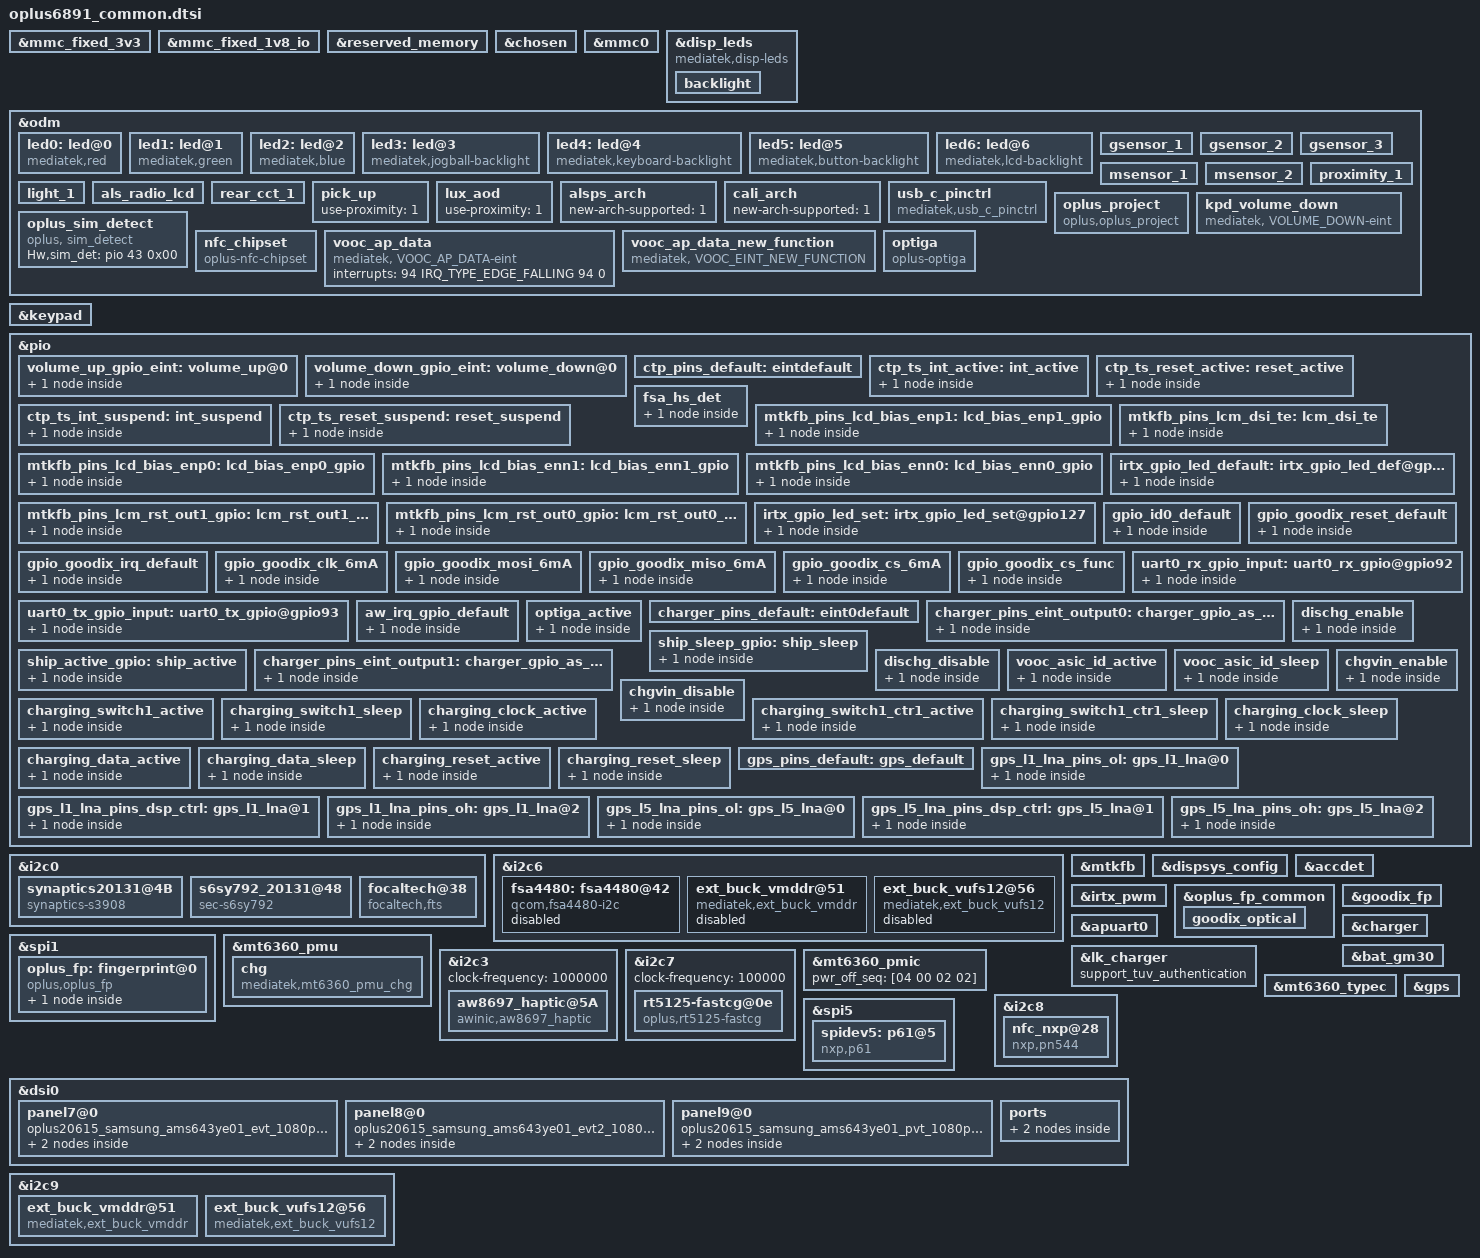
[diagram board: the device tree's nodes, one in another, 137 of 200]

&mmc_fixed_3v3 {
	status = "okay";
	regulator-name = "mmc_power";
	regulator-min-microvolt = <3300000>;
	regulator-max-microvolt = <3300000>;
	enable-active-high;
	regulator-always-on;
};

&mmc_fixed_1v8_io {
	status = "okay";
	regulator-name = "mmc_io";
	regulator-min-microvolt = <1800000>;
	regulator-max-microvolt = <1800000>;
	enable-active-high;
	regulator-always-on;
};

&reserved_memory {
};

/* chosen */
&chosen {

	atag,videolfb-fb_base_l = <0x7e020000>;
	atag,videolfb-fb_base_h = <0x0>;
	atag,videolfb-islcmfound = <1>;
	atag,videolfb-islcm_inited = <0>;
	atag,videolfb-fps= <6000>;
	atag,videolfb-vramSize= <0x1be0000>;
	atag,videolfb-lcmname=
		"nt35595_fhd_dsi_cmd_truly_nt50358_drv";
};

&mmc0 {
	status = "okay";
	/* pinctrl-names = "default", "state_uhs"; */
	/* pinctrl-0 = <&mmc0_pins_default>; */
	/* pinctrl-1 = <&mmc0_pins_uhs>; */
	bus-width = <8>;
	max-frequency = <5000000>;
	cap-mmc-highspeed;
	no-sdio;
	no-sd;
	vmmc-supply = <&mmc_fixed_3v3>;
	vqmmc-supply = <&mmc_fixed_1v8_io>;
	non-removable;
};

&disp_leds {
	compatible = "mediatek,disp-leds";

	backlight {
		label = "lcd-backlight";
		max-brightness = <4095>;
		led-bits = <12>;
		trans-bits = <12>;
		default-state = "on";
	};
};

&odm {
	led0:led@0 {
		compatible = "mediatek,red";
		led_mode = <0>;
		data = <1>;
		pwm_config = <0 0 0 0 0>;
	};
	led1:led@1 {
		compatible = "mediatek,green";
		led_mode = <0>;
		data = <1>;
		pwm_config = <0 0 0 0 0>;
	};
	led2:led@2 {
		compatible = "mediatek,blue";
		led_mode = <0>;
		data = <1>;
		pwm_config = <0 0 0 0 0>;
	};
	led3:led@3 {
		compatible = "mediatek,jogball-backlight";
		led_mode = <0>;
		data = <1>;
		pwm_config = <0 0 0 0 0>;
	};
	led4:led@4 {
		compatible = "mediatek,keyboard-backlight";
		led_mode = <0>;
		data = <1>;
		pwm_config = <0 0 0 0 0>;
	};
	led5:led@5 {
		compatible = "mediatek,button-backlight";
		led_mode = <0>;
		data = <1>;
		pwm_config = <0 0 0 0 0>;
	};
	led6:led@6 {
		compatible = "mediatek,lcd-backlight";
		/*#ifndef OPLUS_FEATURE_BRINGUP*/
		//led_mode = <5>;
		//#else
		led_mode = <4>;
		//#endif
		data = <1>;
		pwm_config = <0 1 0 0 0>;
	};
/* sensor start */
	/*
	enum {
		LIS3DH,
		LSM6DS3,
		BMI160,
		LIS2HH12,
		LSM6DSM,
		BMI2XY,
		LSM6DSO,
		BMA2X2,
		SC7A20,
		ICM4X6XX,
		ICM4N607,
	};
	*/
	gsensor_1: gsensor_1 {
		status = "okay";
		sensor_name = <2>;//BMI160
		device_name = "bmi160";
		i2c_num = <2>;
		i2c_addr = <0>;
		direction = <7>;
		eint_num = <3>;
		step_count_7_en = <1>;
		config_miso = <1>;
		correct_y_bias = <1>;
		gyro_cali_version= <2>;
		acc_cali_range= <250 250 250>; //250mg
	};
	gsensor_2: gsensor_2 {
		status = "okay";
		sensor_name = <6>;//LSM6DSO
		device_name = "lsm6dso";
		i2c_num = <2>;
		i2c_addr = <0>;
		direction = <6>;
		eint_num = <3>;
		gyro_cali_version= <2>;
		acc_cali_range= <200 200 200>; //250mg
	};
	gsensor_3: gsensor_3 {
		status = "okay";
		sensor_name = <10>;//ICM42607
		device_name = "icm4n607";
		i2c_num = <2>;
		i2c_addr = <0>;
		direction = <6>;
		eint_num = <3>;
		gyro_cali_version= <2>;
		acc_cali_range= <300 300 300>; //300mg
	};
	/*
	enum {
		AKM09911,
		MMC3530,
		MMC5603,
		MXG4300,
	};
	*/
	msensor_1: msensor_1 {
		status = "okay";
		sensor_name = <0>;//AKM09911
		i2c_num = <0>;
		i2c_addr = <12>;
		direction = <1>;
		eint_num = <0>;
		soft-mag-parameter = <11168 0 285 1 86 1 218 1 9025 0 78 1 263 1 31 0 10658 0>;
	};
	msensor_2: msensor_2 {
		status = "okay";
		sensor_name = <2>;//MMC5603
		i2c_num = <0>;
		i2c_addr = <48>;
		direction = <1>;
		eint_num = <0>;
		soft-mag-parameter = <9983 0 495 1 111 0 42 0 8099 0 453 1 515 0 155 1 10267 0>;
	};
	/*
	enum {
		TMD2725,
		APSD9922,
		STK3335,
		STK3331,
		STK2232,
		TCS3701,
		STK32600,
	};
	*/
	proximity_1: proximity_1 {
		status = "okay";
		sensor_name = <5>;//TCS3701
		i2c_num = <0>;
		i2c_addr = <57>;
		direction = <4>;
		eint_num = <4>;
		low_step = <300>;
		high_step = <400>;
		low_limit = <400>;
		high_limit = <600>;
		dirty_low_step = <100>;
		dirty_high_step = <150>;
		ps_dirty_limit = <1022>;
		ps_ir_limit = <500>;
		ps_adjust_min = <0>;
		ps_adjust_max = <600>;
		sampling_count = <5>;
		step_max = <400>;
		step_min = <110>;
		step_div = <1500>;
		anti_shake_delta = <80>;
		dynamic_cali_max = <1023>;
		raw2offset_radio = <31200>;
		offset_max = <250>;
		offset_range_min = <255>;
		offset_range_max = <255>;
		force_cali_limit = <2000>;
		cali_jitter_limit = <30>;
		cal_offset_margin = <120>;
	};
	light_1: light_1 {
		status = "okay";
		sensor_name = <5>;//TCS3701
		i2c_num = <0>;
		i2c_addr = <57>;
		direction = <4>;
		eint_num = <4>;
		als_ratio = <110>;
		als_buffer_length =<10>;
		device_name = "tcs3701";
	};
	als_radio_lcd:als_radio_lcd {
		status = "okay";
		samsung_als_radio = <200>;
		boe_als_radio = <150>;
		tianma_als_radio = <150>;
	};
	rear_cct_1: rear_cct_1 {
                status = "okay";
                sensor_name = <1>;//MN29005
                i2c_num = <1>;
                i2c_addr = <0x49>;
                direction = <0>;
                eint_num = <8>;
                available_sensor = <1>; // bit 0: rear als, bit 1: rear cct, bit 2: rear flicker
                device_name = "mn29005";
        };
	pick_up: pick_up {
		status = "okay";
		use-proximity = <1>;
	};
	lux_aod: lux_aod {
		status = "okay";
		use-proximity = <1>;
	};
	alsps_arch: alsps_arch {
		status = "okay";
		new-arch-supported = <1>;
	};
	cali_arch: cali_arch {
		status = "okay";
		new-arch-supported = <1>;
	};
/* sensor end */
	usb_c_pinctrl:usb_c_pinctrl {
		compatible = "mediatek,usb_c_pinctrl";
	};
/*OPLUS_FEATURE_TP_BASIC oplus project start */
	oplus_project:oplus_project {
		compatible = "oplus,oplus_project";
	};
/*endif*/
//#ifdef OPLUS_FEATURE_TP_BASIC
        kpd_volume_down:kpd_volume_down {
                compatible = "mediatek, VOLUME_DOWN-eint";
                interrupt-parent = <&pio>;
                interrupts = <155 IRQ_TYPE_EDGE_FALLING 155 0>;
                debounce = <32000>;
                status = "okay";
        };

//#endif OPLUS_FEATURE_TP_BASIC

//#ifdef OPLUS_FEATURE_TP_BASIC
    oplus_sim_detect {
        compatible = "oplus, sim_detect";
        Hw,sim_det = <&pio 43 0x00>;
    };
//#endif /* OPLUS_FEATURE_TP_BASIC */

    nfc_chipset:nfc_chipset {
        compatible = "oplus-nfc-chipset";
        chipset-20615 = "SN100T";
        chipset-20662 = "SN100T";
    };
//#endif /* OPLUS_FEATURE_NFC_CONSOFT */

};
//#ifdef OPLUS_FEATURE_TP_BASIC
&keypad {
        keypad,volume-up        = <&pio 20 0x00>;
        keypad,volume-down      = <&pio 155 0x00>;
        pinctrl-names = "volume_up_as_int", "volume_down_as_int";
        pinctrl-0 = <&volume_up_gpio_eint>;
        pinctrl-1 = <&volume_down_gpio_eint>;
        status = "okay";
};

&pio {
        volume_up_gpio_eint:volume_up@0{
                pins_cmd_dat {
                        pinmux = <PINMUX_GPIO59__FUNC_GPIO59>;
                        slew-rate = <0>;  /*direction 0:in, 1:out*/
                        input-enable;
                };
        };

        volume_down_gpio_eint:volume_down@0{
                pins_cmd_dat {
                        pinmux = <PINMUX_GPIO155__FUNC_GPIO155>;
                        slew-rate = <0>;  /*direction 0:in, 1:out*/
                        input-enable;
                };
        };
};
//#endif OPLUS_FEATURE_TP_BASIC
//#ifdef OPLUS_FEATURE_TP_BASIC
&i2c0 {

	synaptics20131@4B {
		compatible = "synaptics-s3908";
		reg = <0x4B>;
		chip-name = "S3908";

		/* Interrupt && Irq-gpio */
		interrupt-parent = <&pio>;
		interrupts = <21 0x2008>;

		/* Power Config */
		vdd_2v8-supply  = <&mt_pmic_vtp_ldo_reg>;
		vdd_2v8_volt = <3000000>;
		/* Other HW Resource */

		irq-gpio = <&pio 21 0x2008>;
		reset-gpio = <&pio 20 0x1>;
		pinctrl-names = "default";
		pinctrl-0 = <&ctp_ts_int_active &ctp_ts_reset_suspend>;

		touchpanel,max-num-support = <10>;
                touchpanel,tx-rx-num = <16 36>;
                touchpanel,panel-coords = <5400 12000>;
                touchpanel,display-coords = <1080 2400>;
                touchpanel,touchmajor-limit = <160 270>;
		//touchpanel,elimination-range = <20 200 200>;
                touchpanel,int-mode = <1>; /*0: interrupt and disable, 1:interrupt and not disable*/
		touchpanel,smooth-level = <0 4 6 8 10>;
		touchpanel,sensitive-level = <0 15 30 45 64>;

		vid_len = <2>;
		tp_type = <3>; /*type:8 BOE*/
		platform_support_project = <20131 20133 20255 20257
                				20131 20133 20255 20257>;
		platform_support_project_dir = <20131 20131 20131 20131
                				20131 20131 20131 20131>;
		platform_support_project_commandline = "oplus20131_boe_nt37800_1080p_dsi_cmd","oplus20131_boe_nt37800_1080p_dsi_cmd","oplus20131_boe_nt37800_1080p_dsi_cmd","oplus20131_boe_nt37800_1080p_dsi_cmd",
                					"oplus20131_tianma_nt37701_1080p_dsi_cmd","oplus20131_tianma_nt37701_1080p_dsi_cmd","oplus20131_tianma_nt37701_1080p_dsi_cmd","oplus20131_tianma_nt37701_1080p_dsi_cmd";

		prevention,dead_area_width = <0 0>;
		prevention,makeup_cnt_weight = <4 1 2 2 1>;
		prevention,large_judge_para = <30 8 8>;
		prevention,large_corner_judge_para = <30 5 5 80 80 0>;

		prevention,curved_large_area_width = <500 500 400 3 3>;
		prevention,large_curved_long_judge_para = <7 90 30 15 15 7 4 7 5 3 3>;
		prevention,large_curved_short_judge_para = <7 90 30 0 15 7 4 7 5 2 3>;
		prevention,grip_large_detect_time = <150>;
		prevention,grip_down_delta_time = <150>;
		prevention,curved_screen;

		prevention,condition_judge_para = <40 30>;
		prevention,condition_area_width = <0 0 80 80>;
		prevention,large_area_width = <0 0>;
		prevention,large_corner_width = <0 0 0>;
		prevention,eli_area_width = <0 0 0 0 0 0>;
		prevention,grip_disable_level = <6>;

		/* SW Support Feature Control */
		health_monitor_v2_support;
		black_gesture_support;
		charger_pump_support;
		fw_update_app_support;
		smart_gesture_support;
		game_switch_support;
		kernel_grip_support;
		fingerprint_underscreen_support;
		headset_pump_support;
		pressure_report_support;
		irq_need_dev_resume_ok;
		smooth_level_array_support;
		sensitive_level_array_support;

		/*
		 *Virtual Key Config:
		 *1:touchpanel,button-type: <virtualkey_type  supportted_button-map>
		 *virtualkey_type:
		 *Type 1: using board_properties
		 *Type 2: using same IC (button zone&& touch zone are seprate)
		 *Type 3: using diffrent IC (button zone&& touch zone are seprate)
		 *Type 4: No need of virtual key process
		 *supportted_button-map:select|menu|home|back
		 *
		 *2:touchpanel,button-map
		 *type (X1,Y1)(X2,Y2)(X3,Y3)(Width_X,Hight_Y)--Only when button-type is 0
		 */
		touchpanel,button-type = <4>;
		touchpanel.button-TRx = <0 0>;
	};

	s6sy792_20131@48 {
		compatible = "sec-s6sy792";
		reg = <0x48>;
		chip-name = "S6SY792";

                /* Interrupt && Irq-gpio */
                interrupt-parent = <&pio>;
                interrupts = <21 0x2008>;

                /* Power Config */
                vdd_2v8-supply  = <&mt_pmic_vtp_ldo_reg>;
                vdd_2v8_volt = <3000000>;
                /* Other HW Resource */

                irq-gpio = <&pio 21 0x2008>;
                reset-gpio = <&pio 20 0x1>;
                pinctrl-names = "default";
                pinctrl-0 = <&ctp_ts_int_active &ctp_ts_reset_suspend>;

		touchpanel,max-num-support = <10>;
                touchpanel,tx-rx-num = <16 36>;
                touchpanel,panel-coords = <5400 12000>;
                touchpanel,display-coords = <1080 2400>;
                touchpanel,touchmajor-limit = <160 270>;
                //touchpanel,elimination-range = <20 200 200>;
		touchpanel,smooth-level = <0 1 2 3 4>;
		touchpanel,sensitive-level = <0 1 2 3 4>;

                vid_len = <2>;
                tp_type = <8>; /*type:8 SAMSUNG*/
                platform_support_project = <20131 20133 20255 20257>;
        	platform_support_project_dir = <20131 20131 20131 20131>;
                platform_support_project_commandline = "oplus20131_samsung_ana6705_1080p_dsi_cmd","oplus20131_samsung_ana6705_1080p_dsi_cmd","oplus20131_samsung_ana6705_1080p_dsi_cmd","oplus20131_samsung_ana6705_1080p_dsi_cmd";

		prevention,dead_area_width = <0 0>;
		prevention,makeup_cnt_weight = <4 1 2 2 1>;
		prevention,large_judge_para = <30 8 8>;
		prevention,large_corner_judge_para = <30 5 5 80 80 0>;

		prevention,curved_large_area_width = <500 500 400 3 3>;
		prevention,large_curved_long_judge_para = <7 90 30 15 15 7 4 7 5 3 3>;
		prevention,large_curved_short_judge_para = <7 90 30 0 15 7 4 7 5 2 3>;
		prevention,grip_large_detect_time = <150>;
		prevention,grip_down_delta_time = <150>;
		prevention,curved_screen;

		prevention,condition_judge_para = <40 30>;
		prevention,condition_area_width = <0 0 80 80>;
		prevention,large_area_width = <0 0>;
		prevention,large_corner_width = <0 0 0>;
		prevention,eli_area_width = <0 0 0 0 0 0>;
		prevention,grip_disable_level = <6>;

		/* SW Support Feature Control */
		health_monitor_v2_support;
		black_gesture_support;
		charger_pump_support;
		fw_update_app_support;
		smart_gesture_support;
		game_switch_support;
		kernel_grip_support;
		fingerprint_underscreen_support;
		headset_pump_support;
		pressure_report_support;
		irq_need_dev_resume_ok;
		sec_kernel_grip_para = <21000>;
		smooth_level_array_support;
		sensitive_level_array_support;
		auto_test_need_cal_support;

                /*
                 *Virtual Key Config:
                 *1:touchpanel,button-type: <virtualkey_type  supportted_button-map>
                 *virtualkey_type:
                 *Type 1: using board_properties
                 *Type 2: using same IC (button zone&& touch zone are seprate)
                 *Type 3: using diffrent IC (button zone&& touch zone are seprate)
                 *Type 4: No need of virtual key process
                 *supportted_button-map:select|menu|home|back
                 *
                 *2:touchpanel,button-map
                 *type (X1,Y1)(X2,Y2)(X3,Y3)(Width_X,Hight_Y)--Only when button-type is 0
                 */
                touchpanel,button-type = <4>;
                touchpanel.button-TRx = <0 0>;
	};
	focaltech@38 {
		status = "okay";
		compatible = "focaltech,fts";
                reg = <0x38>;
                chip-name = "FT3518";

		/* Power Config */
		vdd_2v8-supply  = <&mt_pmic_vtp_ldo_reg>;
                vdd_2v8_volt = <3000000>;
               
		/* Interrupt && Irq-gpio */
                /* Other HW Resource */
		irq-gpio = <&pio 21 0x2002>;
		reset-gpio = <&pio 20 0x1>;
		pinctrl-names = "default";
                pinctrl-0 = <&ctp_ts_int_active &ctp_ts_reset_suspend>;

		touchpanel,max-num-support = <10>;
                touchpanel,tx-rx-num = <16 34>;
                touchpanel,panel-coords = <8640 19200>;
                touchpanel,display-coords = <1080 2400>;
                touchpanel,touchmajor-limit = <0 432>;
		tp_type = <8>;
		panel_type = <8>;
		firmware_name = "focalt_";
		platform_support_project = <20619>;
		platform_support_project_dir = <20615>;
		platform_support_project_commandline = "default_commandline","default_commandline";
                /* SW Support Feature Control */
                project_id = <20615>;
		irq_need_dev_resume_ok;
                black_gesture_support;
                fw_edge_limit_support;
                pressure_report_support;
                charger_pump_support;
                game_switch_support;
                smart_gesture_support;
                headset_pump_support;
                fw_update_app_support;
                fingerprint_underscreen_support;
                //esd_handle_support;
		high_resolution_support_x8;
                touchpanel,button-type = <4>;
                touchpanel.button-TRx = <0 0>;
	};
};

&pio {
	ctp_pins_default: eintdefault {
	};
	ctp_ts_int_active: int_active {
		pins_cmd_dat {
			pinmux = <PINMUX_GPIO21__FUNC_GPIO21>;
			slew-rate = <0>;
			bias-pull-up;
		};
	};
	ctp_ts_reset_active: reset_active {
		pins_cmd_dat {
			pinmux = <PINMUX_GPIO20__FUNC_GPIO20>;
			slew-rate = <1>;
			output-high;
		};
	};
	ctp_ts_int_suspend: int_suspend {
		pins_cmd_dat {
			pinmux = <PINMUX_GPIO21__FUNC_GPIO21>;
			slew-rate = <1>;
			output-low;
		};
	};
	ctp_ts_reset_suspend: reset_suspend {
		pins_cmd_dat {
			pinmux = <PINMUX_GPIO20__FUNC_GPIO20>;
			slew-rate = <1>;
			output-low;
		};
	};
};
//#endif OPLUS_FEATURE_TP_BASIC

//#ifdef OPLUS_ARCH_EXTENDS
&i2c6 {
	fsa4480: fsa4480@42 {
		compatible = "qcom,fsa4480-i2c";
		reg = <0x42>;
		pinctrl-names = "default";
		pinctrl-0 = <&fsa_hs_det>;
		fsa4480,hs-det-gpio = <&pio 54 0>;
		status = "disabled";
	};
};

&pio {
	fsa_hs_det: fsa_hs_det {
		pins_cmd_dat {
			pinmux = <PINMUX_GPIO54__FUNC_GPIO54>;
			slew-rate = <1>;  /*direction 0:in, 1:out*/
			output-high;
		};
	};
	/*
	aud_gpio_i2s0_on: aud_gpio_i2s0_on {
		pins_cmd1_dat {
			pinmux = <PINMUX_GPIO34__FUNC_I2S3_DI>;
		};
	};*/
};
//#endif /*OPLUS_ARCH_EXTENDS*/

/* DISPSYS GPIO standardization */
&pio {
	mtkfb_pins_lcd_bias_enp1: lcd_bias_enp1_gpio {
		pins_cmd_dat {
			pinmux = <PINMUX_GPIO28__FUNC_GPIO28>;
			slew-rate = <1>;
			output-high;
		};
	};

	mtkfb_pins_lcd_bias_enp0: lcd_bias_enp0_gpio {
		pins_cmd_dat {
			pinmux = <PINMUX_GPIO28__FUNC_GPIO28>;
			slew-rate = <1>;
			output-low;
		};
	};

	mtkfb_pins_lcd_bias_enn1: lcd_bias_enn1_gpio {
		pins_cmd_dat {
			pinmux = <PINMUX_GPIO29__FUNC_GPIO29>;
			slew-rate = <1>;
			output-high;
		};
	};

	mtkfb_pins_lcd_bias_enn0: lcd_bias_enn0_gpio {
		pins_cmd_dat {
			pinmux = <PINMUX_GPIO29__FUNC_GPIO29>;
			slew-rate = <1>;
			output-low;
		};
	};

	mtkfb_pins_lcm_rst_out1_gpio: lcm_rst_out1_gpio {
		pins_cmd_dat {
			pinmux = <PINMUX_GPIO42__FUNC_GPIO42>;
			slew-rate = <1>;
			output-high;
		};
	};

	mtkfb_pins_lcm_rst_out0_gpio: lcm_rst_out0_gpio {
		pins_cmd_dat {
			pinmux = <PINMUX_GPIO42__FUNC_GPIO42>;
			slew-rate = <1>;
			output-low;
		};
	};

	mtkfb_pins_lcm_dsi_te: lcm_dsi_te {
		pins_cmd_dat {
			pinmux = <PINMUX_GPIO41__FUNC_DSI_TE>;
		};
	};
};

&mtkfb {
	pinctrl-names = "lcd_bias_enp1_gpio", "lcd_bias_enp0_gpio",
		"lcd_bias_enn1_gpio", "lcd_bias_enn0_gpio",
		"lcm_rst_out1_gpio", "lcm_rst_out0_gpio",
		"mode_te_te";
	pinctrl-0 = <&mtkfb_pins_lcd_bias_enp1>;
	pinctrl-1 = <&mtkfb_pins_lcd_bias_enp0>;
	pinctrl-2 = <&mtkfb_pins_lcd_bias_enn1>;
	pinctrl-3 = <&mtkfb_pins_lcd_bias_enn0>;
	pinctrl-4 = <&mtkfb_pins_lcm_rst_out1_gpio>;
	pinctrl-5 = <&mtkfb_pins_lcm_rst_out0_gpio>;
	pinctrl-6 = <&mtkfb_pins_lcm_dsi_te>;
	status = "okay";
};

&dispsys_config {
	pinctrl-names =
		"lcm_rst_out1_gpio", "lcm_rst_out0_gpio",
		"mode_te_te";
	pinctrl-0 = <&mtkfb_pins_lcm_rst_out1_gpio>;
	pinctrl-1 = <&mtkfb_pins_lcm_rst_out0_gpio>;
	pinctrl-2 = <&mtkfb_pins_lcm_dsi_te>;
	status = "okay";
};
/* DISPSYS GPIO standardization end */

/* accdet start */
&accdet {
	/* accdet micbias voltage: 0x09:2.85v 0x08:2.8v 0x07,
	 * 2.7v;0x05,2.5v;0x02,1.9v
	 */
	accdet-mic-vol = <8>;
	/* accdet pwm_width, pwm_thresh, fall_delay, rise_delay
	 * debounce0, debounce1, debounce3, debounce4
	 * eint pwm_width, eint pwm_thresh
	 * eint deb(debounce0, debounce1, debounce2, debounce3), inv_debounce
	 */
	headset-mode-setting = <0x500 0x500 1 0x1f0
				0x800 0x800 0x20 0x44
				0x4 0x1
				0x5 0x3 0x3 0x5 0xe>;
	accdet-plugout-debounce = <1>;
	/*1:ACC mode, 2:low cost without in bias, 6:low cost with in bias*/
	accdet-mic-mode = <2>;
	/*0--MD_MAX--UP_MAX--DW_MAX*/
	headset-three-key-threshold = <0 82 170 306>;
	headset-three-key-threshold-CDD = <0 121 192 600>;
	/*0--MD_MAX--VOICE_MAX--UP_MAX--DW_MAX*/
	headset-four-key-threshold = <0 58 121 192 400>;

	/* select VTH to 2v and 500k, use internal resitance */
	eint_use_ext_res = <0>;
	status = "okay";
};
/* accdet end */

/* IRTX GPIO Start */
&irtx_pwm {
	pinctrl-names = "irtx_gpio_led_default", "irtx_gpio_led_set";
	pinctrl-0 = <&irtx_gpio_led_default>;
	pinctrl-1 = <&irtx_gpio_led_set>;
	status = "okay";
};
&pio {
	/* IRTX GPIO Settings -Start */
	/* default: GPIO0, output, high */
	irtx_gpio_led_default:irtx_gpio_led_def@gpio127 {
		pins_cmd_dat {
			pinmux = <PINMUX_GPIO127__FUNC_GPIO127>;
			slew-rate = <1>;
			bias-disable;
			output-low;
			input-schmitt-enable = <0>;
		};
	};

	irtx_gpio_led_set:irtx_gpio_led_set@gpio127 {
		pins_cmd_dat {
			pinmux = <PINMUX_GPIO127__FUNC_PWM_3>;
			slew-rate = <1>;
			output-high;
		};
	};
}; /* IRTX GPIO Settings -End */

/* FINGERPRINT start */
//ifdef OPLUS_FEATURE_FINGERPRINT
&oplus_fp_common {
    oplus,fp_gpio_num = <1>;
    oplus,fp_gpio_0 = <&pio 190 0x0>;
    pinctrl-names = "default";
    pinctrl-0 = <&gpio_id0_default>;
    goodix_optical {
        oplus,fp-id = <0>; // fp id mapping table
        vendor-chip = <11>; // please refer to the struct fp_vendor_t in oplusfp_commmon.n
        eng-menu = "-1,-1"; // represents SNR, inclination test item in engineer menu, and 0/1 means off/on 
        chip-name = "G_OPTICAL_G3S";  // /proc/fp_id, will be displayed in engineer menu 
	};
};

&pio{
	gpio_id0_default: gpio_id0_default {
		pins_cmd_dat {
			pinmux = <PINMUX_GPIO190__FUNC_GPIO190>;
			slew-rate = <0>;
			bias-pull-up = <00>;
			input-enable;
		};
	};
};

&goodix_fp {
	goodix,gpio_irq = <&pio 15 0x00>;
	goodix,gpio_reset = <&pio 14 0x00>;
	goodix,gpio_cs = <&pio 157 0x00>;
	pinctrl-names = "default", "gf_spi_drive_6mA", "gf_cs_func";
	pinctrl-0 = <&gpio_goodix_irq_default>, <&gpio_goodix_reset_default>;
	pinctrl-1 = <&gpio_goodix_clk_6mA>, <&gpio_goodix_mosi_6mA>, <&gpio_goodix_miso_6mA>, <&gpio_goodix_cs_6mA>;
	pinctrl-2 = <&gpio_goodix_cs_func>;
	status = "okay";
};

&spi1 {
#address-cells = <1>;
#size-cells = <0>;
status = "okay";
oplus_fp: fingerprint@0 {
		 compatible = "oplus,oplus_fp";
		 reg = <0>;
		 spi-max-frequency = <8000000>;
		 spi-id = <1>;
		 spi-irq = <15>;
		 spi-reg = <11010000>;
		 dvdd-supply = <&mt_pmic_vmch_ldo_reg>;
		 dvdd-config = <3300000 3300000 150000>;
		 power-num = <1>;
		 status = "okay";
		 power_source_1 {
			 power-mode = <1>;
			 power-name = "dvdd";
			 power-config = "dvdd-config";
			 delay-time = <0>;
		 };
	 };
};
// 1 = ldo power, refer to oplus_fp_common.h
&pio{
gpio_goodix_reset_default: gpio_goodix_reset_default {
				   pins_cmd_dat {
					   pinmux = <PINMUX_GPIO14__FUNC_GPIO14>;
					   slew-rate = <1>;
					   output-low;
				   };
			   };
gpio_goodix_irq_default: gpio_goodix_irq_default {
				 pins_cmd_dat {
					 pinmux = <PINMUX_GPIO15__FUNC_GPIO15>;
					 slew-rate = <0>;
					 bias-pull-down;
				 };
			 };
gpio_goodix_clk_6mA: gpio_goodix_clk_6mA {
			     pins_cmd_dat {
				      pinmux = <PINMUX_GPIO156__FUNC_SPI1_A_CLK>;
				      drive-strength = <2>;
			     };
		     };
gpio_goodix_mosi_6mA: gpio_goodix_mosi_6mA {
			      pins_cmd_dat {
				      pinmux = <PINMUX_GPIO159__FUNC_SPI1_A_MO>;
				      drive-strength = <2>;
			      };
		      };
gpio_goodix_miso_6mA: gpio_goodix_miso_6mA {
			      pins_cmd_dat {
				      pinmux = <PINMUX_GPIO158__FUNC_SPI1_A_MI>;
				      drive-strength = <3>;
			      };
		      };
gpio_goodix_cs_6mA: gpio_goodix_cs_6mA {
			    pins_cmd_dat {
				    pinmux = <PINMUX_GPIO157__FUNC_SPI1_A_CSB>;
				    drive-strength = <2>;
			    };
		    };
gpio_goodix_cs_func: gpio_goodix_cs_func {
			     pins_cmd_dat {
				     pinmux = <PINMUX_GPIO157__FUNC_SPI1_A_CSB>;
				     drive-strength = <2>;
			     };
		     };
};
//#endif OPLUS_FEATURE_FINGERPRINT
/* FINGERPRINT end */

&apuart0 {
	pinctrl-names = "uart0_rx_gpio",
			"uart0_tx_gpio";
	pinctrl-0 = <&uart0_rx_gpio_input>;
	pinctrl-1 = <&uart0_tx_gpio_input>;
	status = "okay";
};

&pio {
	uart0_rx_gpio_input:uart0_rx_gpio@gpio92 {
		pins_cmd_dat {
			pinmux = <PINMUX_GPIO92__FUNC_GPIO92>;
			input-enable;
			slew-rate = <0>;
			bias-disable;
		};
	};
	uart0_tx_gpio_input:uart0_tx_gpio@gpio93 {
		pins_cmd_dat {
			pinmux = <PINMUX_GPIO93__FUNC_GPIO93>;
			input-enable;
			slew-rate = <0>;
			bias-disable;
		};
	};
};

&mt6360_pmu {
	chg {
		compatible = "mediatek,mt6360_pmu_chg";
		interrupt-parent = <&mt6360_pmu>;
		interrupts = <4 0>, <6 0>, <7 0>, <9 0>,
				<12 0>, <13 0>, <14 0>, <15 0>,
				<27 0>, <29 0>, <30 0>, <32 0>,
				<35 0>, <40 0>, <48 0>, <60 0>,
				<53 0>;
		interrupt-names = "chg_treg_evt", "chg_mivr_evt",
				"pwr_rdy_evt", "chg_batsysuv_evt",
				"chg_vsysuv_evt", "chg_vsysov_evt",
				"chg_vbatov_evt", "chg_vbusov_evt",
				"chg_tmri", "chg_adpbadi",
				"chg_rvpi",  "chg_aiccmeasl",
				"wdtmri", "pumpx_donei",
				"attachi", "chrdet_ext_evt",
				"hvdcp_det";
		io-channels = <&adc 0>, <&adc 1>, <&adc 3>, <&adc 4>,
				<&adc 5>, <&adc 6>, <&adc 8>, <&adc 10>;
		io-channel-names = "USBID", "VBUSDIV5", "VSYS", "VBAT",
				"IBUS", "IBAT", "TEMP_JC", "TS";
		chg_name = "primary_chg";
		ichg = <2000000>;               /* uA */
		aicr = <500000>;                /* uA */
		mivr = <4400000>;               /* uV */
		cv = <4350000>;                 /* uA */
		ieoc = <150000>;                /* uA */
		safety_timer = <12>;            /* hour */
		ircmp_resistor = <25000>;       /* uohm */
		ircmp_vclamp = <32000>;         /* uV */
		en_te = <1>;
		en_wdt = <1>;
		aicc_once = <1>;
		post_aicc = <1>;
		batoc_notify = <0>;
	};
};
&lk_charger{
	support_tuv_authentication;
};
&charger {
	io-channels =  <&auxadc 3>,<&auxadc 4>,
		<&auxadc 5>;
	io-channel-names = "auxadc3-subboard_temp","auxadc4-usb_temp_v_l",
		"auxadc5-usb_temp_v_r";

	pinctrl-names = "default", "dischg_enable", "dischg_disable" ,"charger_gpio_as_output_low", "charger_gpio_as_output_high",
	"chgvin_enable", "chgvin_disable","ship_sleep", "ship_active";
	pinctrl-0 = <&charger_pins_default>;
	pinctrl-1 = <&dischg_enable>;
	pinctrl-2 = <&dischg_disable>;
	pinctrl-3 = <&charger_pins_eint_output0>;      //USB_ON -> USB_SWITCH:(UART && USB)
	pinctrl-4 = <&charger_pins_eint_output1>;
	pinctrl-5 = <&chgvin_enable>;
	pinctrl-6 = <&chgvin_disable>;
	pinctrl-7 = <&ship_sleep_gpio>;
	pinctrl-8 = <&ship_active_gpio>;

	/*for oplus chg framework:*/
	qcom,input_current_charger_ma = <2000>;
	qcom,input_current_usb_ma = <500>;
	qcom,input_current_cdp_ma = <1500>;
	qcom,input_current_led_ma = <1200>;
	qcom,input_current_led_ma_high = <1200>;
        qcom,input_current_led_ma_warm = <1500>;
        qcom,input_current_led_ma_normal = <2000>;
        qcom,input_current_led_ma_forcmcc = <500>;
        qcom,input_current_camera_ma = <2000>;
        qcom,input_current_calling_ma = <1500>;
        qcom,qc_input_current_charger_ma = <2200>;
        qcom,pd_input_current_charger_ma = <3300>;

        qcom,iterm_disabled = <0>;
	qcom,iterm_ma = <235>;
	qcom,recharge-mv = <100>;
	qcom,batt_capacity_mah = <4500>;/*typical capacity*/

	qcom,removed_bat_decidegc = <190>;  /*<-19C*/

        qcom,cold_bat_decidegc = <20>;  /* -2C ~ 0C */
        qcom,temp_cold_vfloat_mv = <3980>;
        qcom,temp_cold_fastchg_current_ma = <300>;

        qcom,little_cold_bat_decidegc = <0>;    /* 0C ~ 5C */
        qcom,temp_little_cold_vfloat_mv = <4435>;
        qcom,temp_little_cold_fastchg_current_ma_high = <2200>;
        qcom,temp_little_cold_fastchg_current_ma_low = <2200>;
        qcom,temp_little_cold_fastchg_current_ma = <1076>;
        qcom,qc_temp_little_cold_fastchg_current_ma_high = <2594>;
        qcom,qc_temp_little_cold_fastchg_current_ma_low = <3300>;
        qcom,pd_temp_little_cold_fastchg_current_ma_high = <2594>;
        qcom,pd_temp_little_cold_fastchg_current_ma_low = <3300>;

        qcom,cool_bat_decidegc = <50>;  /* 5C ~ 12C */
        qcom,temp_cool_vfloat_mv = <4435>;
        qcom,temp_cool_fastchg_current_ma_high = <2200>;
        qcom,temp_cool_fastchg_current_ma_low = <2200>;
        qcom,qc_temp_cool_fastchg_current_ma_high = <3300>;
        qcom,qc_temp_cool_fastchg_current_ma_low = <3300>;
        qcom,pd_temp_cool_fastchg_current_ma_high = <3300>;
        qcom,pd_temp_cool_fastchg_current_ma_low = <3300>;

        qcom,little_cool_bat_decidegc = <120>;  /* 12C ~ 16C */
        qcom,temp_little_cool_vfloat_mv = <4435>;
        qcom,temp_little_cool_fastchg_current_ma = <2200>;
        qcom,pd_temp_little_cool_fastchg_current_ma = <3300>;
        qcom,qc_temp_little_cool_fastchg_current_ma = <3300>;

        qcom,normal_bat_decidegc = <160>;       /* 16C ~ 45C */
        qcom,temp_normal_vfloat_mv = <4435>;
        qcom,temp_normal_fastchg_current_ma = <2200>;
        qcom,pd_temp_normal_fastchg_current_ma = <3300>;
        qcom,qc_temp_normal_fastchg_current_ma = <3300>;

        qcom,warm_bat_decidegc = <450>;         /* 45C ~ 53C */ /*8pin Bat Vooc project need add 3 degree C*/
        qcom,temp_warm_vfloat_mv = <4130>;
        qcom,temp_warm_fastchg_current_ma = <1152>;
        qcom,pd_temp_warm_fastchg_current_ma = <1152>;
        qcom,qc_temp_warm_fastchg_current_ma = <1152>;
        qcom,temp_warm_fastchg_current_ma_led_on = <500>;

	qcom,hot_bat_decidegc = <530>;  /* > 53C */

	qcom,non_standard_vfloat_mv = <3980>;
	qcom,non_standard_fastchg_current_ma = <512>;

	qcom,short_c_bat_cv_mv = <4330>;
	qcom,short_c_bat_vfloat_mv = <3800>;
	qcom,short_c_bat_fastchg_current_ma = <512>;
	qcom,short_c_bat_vfloat_sw_limit = <3750>;

	qcom,cold_vfloat_sw_limit = <3930>;
	qcom,little_cold_vfloat_sw_limit = <4385>;
	qcom,cool_vfloat_sw_limit = <4385>;
	qcom,little_cool_vfloat_sw_limit = <4385>;
	qcom,normal_vfloat_sw_limit = <4385>;
	qcom,warm_vfloat_sw_limit = <4080>;
	qcom,non_standard_vfloat_sw_limit = <3930>;

	qcom,max_chg_time_sec = <64800>;
	qcom,charger_hv_thr = <5900>;
	qcom,charger_recv_thr = <5500>;
	qcom,charger_lv_thr = <3400>;
	qcom,vbatt_full_thr = <4400>;
	qcom,vbatt_hv_thr = <4550>;

	qcom,vfloat_step_mv = <8>;
	qcom,non_standard_vfloat_over_sw_limit = <3990>;
	qcom,cold_vfloat_over_sw_limit = <3990>;
	qcom,little_cold_vfloat_over_sw_limit = <4445>;
	qcom,cool_vfloat_over_sw_limit = <4445>;
	qcom,little_cool_vfloat_over_sw_limit = <4445>;
	qcom,normal_vfloat_over_sw_limit = <4445>;
	qcom,warm_vfloat_over_sw_limit = <4140>;

	qcom,vbatt_power_off = <3300>;
	qcom,vbatt_soc_1 = <3310>;
	qcom,vooc_project = <1>;
	qcom,vbatt_num = <1>;
	qcom,new_ui_warning_support;
	qcom,internal_gauge_with_asic = <1>;

	qcom,ffc_support;
	qcom,dual_ffc;
	qcom,nightstandby_support;
	qcom,chargerid_support;

	qcom,normal_vterm_hw_inc = <18>;
	qcom,non_normal_vterm_hw_inc = <18>;

	qcom,ff1_normal_fastchg_ma = <1500>;
	qcom,ff1_warm_fastchg_ma = <1750>;	/* 35C ~ 40c */
	qcom,ff1_exit_step_ma = <150>;
	qcom,ff1_warm_exit_step_ma = <150>;
	qcom,ffc2_normal_fastchg_ma = <1500>;/*12C~35c*/
	qcom,ffc2_warm_fastchg_ma = <1750>;	/* 35C ~ 40c */
	qcom,ffc2_temp_warm_decidegc = <350>;
	qcom,ffc2_temp_high_decidegc = <400>;
	qcom,ffc2_temp_low_decidegc = <160>;
	qcom,ffc2_exit_step_ma = <150>;
	qcom,ffc2_warm_exit_step_ma = <150>;

	qcom,ffc_normal_vfloat_sw_limit = <4485>;/* exit volt*/
	qcom,ffc2_normal_vfloat_sw_limit = <4485>;/* exit volt*/
	qcom,ffc_temp_normal_vfloat_mv = <4550>;/*input volt*/
	qcom,ffc_normal_vfloat_over_sw_limit = <4500>;/*protect volt*/

	qcom,overchg_normal_fastchg_ma = <700>;/*16C~35c*/
	qcom,overchg_temp_warm_decidegc = <350>;
	qcom,overchg_warm_fastchg_ma = <750>;/*35C~40c*/
	qcom,overchg_temp_high_decidegc = <400>;

	qcom,overchg_normal_vfloat_sw_limit = <4450>;
	qcom,overchg_temp_normal_vfloat_mv = <4500>;
	qcom,overchg_normal_vfloat_over_sw_limit = <4500>;
	qcom,default_iterm_ma = <235>;
	qcom,default_temp_normal_fastchg_current_ma = <2000>;
	qcom,default_normal_vfloat_sw_limit = <4385>;
	qcom,default_temp_normal_vfloat_mv = <4435>;
	qcom,default_normal_vfloat_over_sw_limit = <4445>;

	//for control:
	//qcom,suspend_after_full;
	qcom,check_batt_full_by_sw;
	//qcom,external_gauge;
	qcom,chg_ctrl_by_calling;
	qcom,chg_ctrl_by_lcd;
	qcom,chg_ctrl_by_camera;
	qcom,sw_vfloat_over_protect_enable;
	qcom,support_ntc_01c_precision;
	qcom,smart_charging_screenoff;
	qcom,usbtemp_lowvbus_detect;
	qcom,vooc_show_ui_soc_decimal;
	qcom,ui_soc_decimal_speedmin = <20>;

	qcom,usbtemp_batttemp_gap = <12>;
	//GPIO config:
	qcom,chargerid_switch-gpio = <&pio 192 0x00>;
	qcom,dischg-gpio = <&pio 51 0x00>;
	qcom,chgvin = <&pio 9 0x00>;
	qcom,pmic_chgfunc = <&pio 26 0x00>;
	qcom,ship-gpio = <&pio 126 0x00>;

};

&bat_gm30 {
	FUELGAGUE_APPLY = <(1)>;
	ENABLE_IS_FORCE_FULL = <1>;
	CAR_TUNE_VALUE = <(95)>;
	/*The resistance of PCB*/
	R_FG_VALUE = <(5)>;
};


&i2c3 {
    status = "okay";
	clock-frequency = <1000000>;
	
	/* AWINIC AW8697 Haptic */
	aw8697_haptic@5A {
		status = "okay";
		compatible = "awinic,aw8697_haptic";
		reg = <0x5A>;
		reset-gpio = <&pio 185 0x01>;
		irq-gpio = <&pio 135 0x2008>;
		qcom,device_id = <832>;//19065

		pinctrl-names = "default";
		pinctrl-0 = <&aw_irq_gpio_default>;
	};
};

&pio{
	aw_irq_gpio_default: aw_irq_gpio_default {		//check
		pins_cmd_dat {
			pinmux = <PINMUX_GPIO135__FUNC_GPIO135>;
			input-enable;
			slew-rate = <0>;
			bias-pull-up = <11>;
		};
	};

};

&odm {
	vooc_ap_data:vooc_ap_data {
		compatible = "mediatek, VOOC_AP_DATA-eint";
		interrupts = <94 IRQ_TYPE_EDGE_FALLING 94 0>;
	};
	vooc_ap_data_new_function:vooc_ap_data_new_function {
		compatible = "mediatek, VOOC_EINT_NEW_FUNCTION";
	};
};
&odm {
	optiga {
		compatible = "oplus-optiga";
		status = "ok";
		pinctrl-names = "optiga_active";
		pinctrl-0 = <&optiga_active>;
		data-gpio = <&pio 183 0x00>;
		cpu-id = <7>;
		key-id = <1>;
	};
};

&pio {
	optiga_active: optiga_active {
		pins_cmd_dat {
			pinmux = <PINMUX_GPIO183__FUNC_GPIO183>;
			//slew-rate = <1>;
			bias-pull-up;
		};
	};
};

&i2c7 {
	status = "okay";
	clock-frequency = <100000>;
	rt5125-fastcg@0e{
		status = "okay";
		compatible = "oplus,rt5125-fastcg";
		reg = <0x0e>;
		qcom,vooc_reply_mcu_bits = <7>;
		qcom,vooc-low-temp = <0>;
		qcom,oplus_batt_4400mv;
		qcom,vooc-high-soc = <90>;
//		qcom,vooc_fw_update_newmethod;
		qcom,vooc-fw-type = <5>;
		qcom,vooc_cool_bat_volt = <3650>;
		qcom,vooc_little_cool_bat_volt = <3550>;
		qcom,vooc_normal_bat_volt = <3450>;
		qcom,vooc_warm_bat_volt = <3350>;

		qcom,vooc_cool_bat_suspend_volt = <3650>;
		qcom,vooc_little_cool_bat_suspend_volt = <3550>;
		qcom,vooc_normal_bat_suspend_volt = <3450>;
		qcom,vooc_warm_bat_suspend_volt = <3350>;
		qcom,vooc_is_platform_gauge;
		qcom,vooc_multistep_adjust_current_support;
		qcom,vooc_multistep_initial_batt_temp = <1000>;
		qcom,vooc-high-temp = <430>;
		qcom,vooc_batt_over_high_temp = <440>;
		qcom,vooc_batt_over_low_temp = <45>;
		qcom,vooc_over_high_or_low_current = <0x0>;
		qcom,vooc_strategy_normal_current = <0x0b>;

		qcom,vooc_strategy1_batt_high_temp0 = <395>;
		qcom,vooc_strategy1_batt_high_temp1 = <420>;
		qcom,vooc_strategy1_batt_high_temp2 = <440>;
		qcom,vooc_strategy1_batt_low_temp2 = <420>;
		qcom,vooc_strategy1_batt_low_temp1 = <395>;
		qcom,vooc_strategy1_batt_low_temp0 = <385>;

		qcom,vooc_strategy1_high_current0 = <0x0b>;
		qcom,vooc_strategy1_high_current1 = <0x0b>;
		qcom,vooc_strategy1_high_current2 = <0x07>;
		qcom,vooc_strategy1_low_current2 = <0x07>;
		qcom,vooc_strategy1_low_current1 = <0x0b>;
		qcom,vooc_strategy1_low_current0 = <0x0b>;
		qcom,vooc_current_lvl = <1000
									1500
									2000
									2500
									3000
									3500
									4000
									4500
									5000
									5500
									6000
									6500
									7000
									7500
									8000
									8500
									9000
									9500
									10000
									10500
									11000
									11500
									12000
									12500>;

		pinctrl-names = "switch1_act_switch2_act", "switch1_sleep_switch2_sleep",
						"switch1_act_switch3_act", "switch1_sleep_switch3_sleep",
						"switch1_act_switch2_sleep", "switch1_sleep_switch2_act",
						"clock_active","clock_sleep",
						"data_active","data_sleep",
						"reset_active","reset_sleep",
						"vooc_asic_id_active","vooc_asic_id_sleep";
		pinctrl-0 = <&charging_switch1_active>;
		pinctrl-1 = <&charging_switch1_sleep>;
		pinctrl-2 = <&charging_switch1_active>;
		pinctrl-3 = <&charging_switch1_sleep>;
		pinctrl-4 = <&charging_switch1_active>;
		pinctrl-5 = <&charging_switch1_sleep>;
		pinctrl-6 = <&charging_clock_active>;
		pinctrl-7 = <&charging_clock_sleep>;
		pinctrl-8 = <&charging_data_active>;
		pinctrl-9 = <&charging_data_sleep>;
		pinctrl-10 = <&charging_reset_active>;
		pinctrl-11 = <&charging_reset_sleep>;
		pinctrl-12 = <&vooc_asic_id_active>;
		pinctrl-13 = <&vooc_asic_id_sleep>;

		qcom,charging_switch1-gpio 		= <&pio 191 0x00>;              //SW_CTRL
		//qcom,charging_switch1_ctr1-gpio 	= <&pio 148 0x00>;

		qcom,charging_reset-gpio 			= <&pio 189 0x00>;//MCU_EN
		qcom,charging_clock-gpio 			= <&pio 95 0x00>;//AP_CLK
		qcom,charging_data-gpio 			= <&pio 94 0x00>;//AP_DATA
		qcom,vooc_asic_id-gpio				= <&pio 56 0x00>;
	};
};



&pio {
	charger_pins_default: eint0default {
	};

	charger_pins_eint_output0: charger_gpio_as_output_low {		//check
		pins_cmd_dat {
			pinmux = <PINMUX_GPIO192__FUNC_GPIO192>;
			slew-rate = <1>;
			output-low;
		};
	};
	ship_sleep_gpio: ship_sleep {
		pins_cmd_dat {
			pinmux = <PINMUX_GPIO126__FUNC_GPIO126>;
			slew-rate = <1>;
			output-low;
		};
	};
	ship_active_gpio: ship_active {
		pins_cmd_dat {
			pinmux = <PINMUX_GPIO126__FUNC_GPIO126>;
			slew-rate = <1>;
			output-high;
		};
	};

	charger_pins_eint_output1: charger_gpio_as_output_high {	//check
		pins_cmd_dat {
			pinmux = <PINMUX_GPIO192__FUNC_GPIO192>;
			slew-rate = <1>;
			output-high;
		};
	};


	dischg_enable: dischg_enable {
		pins_cmd_dat {
			pinmux = <PINMUX_GPIO51__FUNC_GPIO51>;		//check
			slew-rate = <1>;							//0:input direction 1:output direction
			bias-pull-up = <00>;
			output-high;
		};
	};

	dischg_disable: dischg_disable {
		pins_cmd_dat {
			pinmux = <PINMUX_GPIO51__FUNC_GPIO51>;		//check
			slew-rate = <1>;
			bias-pull-down = <00>;
			output-low;
		};
	};

	vooc_asic_id_active: vooc_asic_id_active {
		pins_cmd_dat {
			pinmux = <PINMUX_GPIO56__FUNC_GPIO56>;
			input-enable;
			slew-rate = <0>;
			bias-pull-up;
		};
	};

	vooc_asic_id_sleep: vooc_asic_id_sleep {
		pins_cmd_dat {
			pinmux = <PINMUX_GPIO56__FUNC_GPIO56>;
			input-enable;
			slew-rate = <0>;
			bias-pull-down;
		};
	};


	//Lukaili Add for camera flash led 
	chgvin_enable: chgvin_enable {
		pins_cmd_dat {
			pinmux = <PINMUX_GPIO9__FUNC_GPIO9>;				//check
			slew-rate = <1>;//0:input direction 1:output direction
			bias-pull-up = <00>;
			output-low;
		};
	};

	chgvin_disable: chgvin_disable {
		pins_cmd_dat {
			pinmux = <PINMUX_GPIO9__FUNC_GPIO9>;			//check
			slew-rate = <1>;
			bias-pull-down = <00>;
			output-high;
		};
	};

	//end Add for camera flash led 
};

&pio {
	charging_switch1_active: charging_switch1_active {
		pins_cmd_dat {
			pinmux = <PINMUX_GPIO191__FUNC_GPIO191>;		//check
			slew-rate = <1>;
			output-high;
		};
	};

	charging_switch1_sleep: charging_switch1_sleep {
		pins_cmd_dat {
			pinmux = <PINMUX_GPIO191__FUNC_GPIO191>;		//check
			slew-rate = <1>;
			output-low;
		};
	};

	charging_switch1_ctr1_active: charging_switch1_ctr1_active {
		pins_cmd_dat {
			pinmux = <PINMUX_GPIO163__FUNC_GPIO163>;		//empty
			slew-rate = <1>;
			bias-pull-up = <00>;
		};
	};
	charging_switch1_ctr1_sleep: charging_switch1_ctr1_sleep {
		pins_cmd_dat {
			pinmux = <PINMUX_GPIO163__FUNC_GPIO163>;		//empty
			slew-rate = <1>;
			output-low;
		};
	};
	
	charging_clock_active: charging_clock_active {
		pins_cmd_dat {
			pinmux = <PINMUX_GPIO95__FUNC_GPIO95>;		//check
			slew-rate = <0>;
			bias-pull-up;
		};
	};

	charging_clock_sleep: charging_clock_sleep {
		pins_cmd_dat {
			pinmux = <PINMUX_GPIO95__FUNC_GPIO95>;		//check
			slew-rate = <0>;
			bias-pull-down;
		};
	};

	charging_data_active: charging_data_active {
		pins_cmd_dat {
			pinmux = <PINMUX_GPIO94__FUNC_GPIO94>;		//check
			slew-rate = <0>;
			bias-pull-down;
		};
	};

	charging_data_sleep: charging_data_sleep {
		pins_cmd_dat {
			pinmux = <PINMUX_GPIO94__FUNC_GPIO94>;		//check
			slew-rate = <0>;
			bias-pull-down;
		};
	};

	charging_reset_active: charging_reset_active {
		pins_cmd_dat {
			pinmux = <PINMUX_GPIO189__FUNC_GPIO189>;	//check
			slew-rate = <1>;
			output-high;
		};
	};

	charging_reset_sleep: charging_reset_sleep {
		pins_cmd_dat {
			pinmux = <PINMUX_GPIO189__FUNC_GPIO189>;	//check
			slew-rate = <1>;
			output-low;
		};
	};


};

&mt6360_pmu {
	mt6360,intr_gpio_num = <24>; /* direct defined GPIO num */
	mt6360,intr_gpio = <&pio 24 0x0>;
	disable_lpsd = <1>;
};

&mt6360_pmic {
	pwr_off_seq = [04 00 02 02];
};

&mt6360_typec {
	mt6360pd,intr_gpio_num = <25>; /* direct defined GPIO num */
	mt6360pd,intr_gpio = <&pio 25 0x0>;
};

/* USB SWITCH GPIO start */
//#ifdef OPLUS_ARCH_EXTENDS
//#endif
/*
&pio {
	usb_default: usb_default {
	};

	gpio_redriver_c1_init: c1_init {
		pins_cmd_dat {
			pinmux = <PINMUX_GPIO113__FUNC_GPIO113>;
			slew-rate = <1>;
			output-low;
		};
	};

	gpio_redriver_c1_low: c1_low {
		pins_cmd_dat {
			pinmux = <PINMUX_GPIO113__FUNC_GPIO113>;
			slew-rate = <1>;
			output-low;
		};
	};

	gpio_redriver_c1_hiz: c1_highz {
		pins_cmd_dat {
			pinmux = <PINMUX_GPIO113__FUNC_GPIO113>;
			slew-rate= <0>;
			bias-disable;
		};
	};

	gpio_redriver_c1_high: c1_high {
		pins_cmd_dat {
			pinmux = <PINMUX_GPIO113__FUNC_GPIO113>;
			slew-rate = <1>;
			output-high;
		};
	};

	gpio_redriver_c2_init: c2_init {
		pins_cmd_dat {
			pinmux = <PINMUX_GPIO112__FUNC_GPIO112>;
			slew-rate = <1>;
			output-low;
		};
	};

	gpio_redriver_c2_low: c2_low {
		pins_cmd_dat {
			pinmux = <PINMUX_GPIO112__FUNC_GPIO112>;
			slew-rate = <1>;
			output-low;
		};
	};

	gpio_redriver_c2_hiz: c2_highz {
		pins_cmd_dat {
			pinmux = <PINMUX_GPIO112__FUNC_GPIO112>;
			slew-rate= <0>;
			bias-disable;
		};
	};

	gpio_redriver_c2_high: c2_high {
		pins_cmd_dat {
			pinmux = <PINMUX_GPIO112__FUNC_GPIO112>;
			slew-rate = <1>;
			output-high;
		};
	};

	gpio_u3_switch_sel1: u3_sw_sel1 {
		pins_cmd_dat {
			pinmux = <PINMUX_GPIO111__FUNC_GPIO111>;
			slew-rate = <1>;
			output-low;
		};
	};

	gpio_u3_switch_sel2: u3_sw_sel2 {
		pins_cmd_dat {
			pinmux = <PINMUX_GPIO111__FUNC_GPIO111>;
			slew-rate = <1>;
			output-high;
		};
	};

	gpio_u3_switch_enable: u3_sw_en {
	};

	gpio_u3_switch_disable: u3_sw_dis {
	};
};

&usb_c_pinctrl {
	pinctrl-names = "usb_default",
		"redrv_c1_init",
		"redrv_c1_low",
		"redrv_c1_hiz",
		"redrv_c1_high",
		"redrv_c2_init",
		"redrv_c2_low",
		"redrv_c2_hiz",
		"redrv_c2_high",
		"switch_sel1",
		"switch_sel2",
		"switch_enable",
		"switch_disable";

	pinctrl-0 = <&usb_default>;
	pinctrl-1 = <&gpio_redriver_c1_init>;
	pinctrl-2 = <&gpio_redriver_c1_low>;
	pinctrl-3 = <&gpio_redriver_c1_hiz>;
	pinctrl-4 = <&gpio_redriver_c1_high>;
	pinctrl-5 = <&gpio_redriver_c2_init>;
	pinctrl-6 = <&gpio_redriver_c2_low>;
	pinctrl-7 = <&gpio_redriver_c2_hiz>;
	pinctrl-8 = <&gpio_redriver_c2_high>;
	pinctrl-9 = <&gpio_u3_switch_sel1>;
	pinctrl-10 = <&gpio_u3_switch_sel2>;
	pinctrl-11 = <&gpio_u3_switch_enable>;
	pinctrl-12 = <&gpio_u3_switch_disable>;
	status = "okay";

	usb_switch-data {
		en_pin_num = <0>;
		en_pin_val = <0>;
		sel_pin_num = <111>;
		sel_pin_val = <1>;
		c1_pin_num = <113>;
		c1_pin_val = <2>;
		c2_pin_num = <112>;
		c2_pin_val = <1>;
	};
};
*/
/* USB SWITCH GPIO end */

//#ifdef OPLUS_FEATURE_NFC_BRINGUP
&i2c8 {
       status = "okay";
       nfc_nxp@28 {
               compatible = "nxp,pn544";
               reg = <0x28>;
               nxp,pn544-irq = <&pio 7 0x0>;
               nxp,pn544-ven = <&pio 16 0x0>;
               nxp,pn544-fw-dwnld = <&pio 6 0x0>;
               nxp,pn544-clkreq = <&pio 17 0x0>;
               interrupt-parent = <&pio>;
       };
};

&spi5 {
       status = "okay";
       #address-cells = <1>;
       #size-cells = <0>;
       spidev5: p61@5 {
       compatible = "nxp,p61";
       reg = <0>;
       spi-max-frequency = <19200000>;
       };
};
//#endif /* OPLUS_FEATURE_NFC_BRINGUP */

/* GPS GPIO standardization start */
&pio {
	gps_pins_default: gps_default {
	};

	gps_l1_lna_pins_ol: gps_l1_lna@0 {
		pins_cmd_dat {
			pinmux = <PINMUX_GPIO162__FUNC_GPIO162>;
			output-low;
		};
	};
	gps_l1_lna_pins_dsp_ctrl: gps_l1_lna@1 {
		pins_cmd_dat {
			pinmux = <PINMUX_GPIO162__FUNC_GPS_L1_ELNA_EN>;
		};
	};
	gps_l1_lna_pins_oh: gps_l1_lna@2 {
		pins_cmd_dat {
			pinmux = <PINMUX_GPIO162__FUNC_GPIO162>;
			output-high;
		};
	};

	gps_l5_lna_pins_ol: gps_l5_lna@0 {
		pins_cmd_dat {
			pinmux = <PINMUX_GPIO163__FUNC_GPIO163>;
			output-low;
		};
	};
	gps_l5_lna_pins_dsp_ctrl: gps_l5_lna@1 {
		pins_cmd_dat {
			pinmux = <PINMUX_GPIO163__FUNC_GPS_L5_ELNA_EN>;
		};
	};
	gps_l5_lna_pins_oh: gps_l5_lna@2 {
		pins_cmd_dat {
			pinmux = <PINMUX_GPIO163__FUNC_GPIO163>;
			output-high;
		};
	};
};

&gps {
	pinctrl-names = "default",
		"gps_l1_lna_disable",
		"gps_l1_lna_dsp_ctrl",
		"gps_l1_lna_enable",
		"gps_l5_lna_disable",
		"gps_l5_lna_dsp_ctrl",
		"gps_l5_lna_enable";
	pinctrl-0 = <&gps_pins_default>;
	pinctrl-1 = <&gps_l1_lna_pins_ol>;
	pinctrl-2 = <&gps_l1_lna_pins_dsp_ctrl>;
	pinctrl-3 = <&gps_l1_lna_pins_oh>;
	pinctrl-4 = <&gps_l5_lna_pins_ol>;
	pinctrl-5 = <&gps_l5_lna_pins_dsp_ctrl>;
	pinctrl-6 = <&gps_l5_lna_pins_oh>;
	status = "okay";
};
/* GPS GPIO standardization end */

&dsi0 {
	status = "okay";
	#address-cells = <1>;
	#size-cells = <0>;
	panel7@0 {
		compatible = "oplus20615_samsung_ams643ye01_evt_1080p_dsi_cmd";
		reg = <0>;
		pm-enable-gpios = <&pio 41 0>;
		reset-gpios = <&pio 42 0>;
		bias-gpios = <&pio 29 0>;
		ldo3-supply = <&mt_pmic_vmc_ldo_reg>;
		pinctrl-names = "default";
		port {
			panel_in7: endpoint {
				remote-endpoint = <&dsi_out>;
			};
		};
	};
	panel8@0 {
                compatible = "oplus20615_samsung_ams643ye01_evt2_1080p_dsi_cmd";
                reg = <1>;
                pm-enable-gpios = <&pio 41 0>;
                reset-gpios = <&pio 42 0>;
                bias-gpios = <&pio 29 0>;
                ldo3-supply = <&mt_pmic_vmc_ldo_reg>;
                pinctrl-names = "default";
                port {
                        panel_in8: endpoint {
                                remote-endpoint = <&dsi_out>;
                        };
                };
        };
        panel9@0 {
                compatible = "oplus20615_samsung_ams643ye01_pvt_1080p_dsi_cmd";
                reg = <2>;
                pm-enable-gpios = <&pio 41 0>;
                reset-gpios = <&pio 42 0>;
//              bias-gpios = <&pio 29 0>;
                ldo3-supply = <&mt_pmic_vmc_ldo_reg>;
                pinctrl-names = "default";
                port {
                        panel_in9: endpoint {
                                remote-endpoint = <&dsi_out>;
                        };
                };
        };
	ports {
		port {
			dsi_out: endpoint {
				remote-endpoint = <&panel_in7>;
			};
		};
	};
};

&i2c6 {
        ext_buck_vmddr@51 {
            compatible = "mediatek,ext_buck_vmddr";
            reg = <0x51>;
            regulator-name = "ext_buck_vmddr";
            regulator-min-microvolt = <300000>;
            regulator-max-microvolt = <1300000>;
            status = "disabled";
        };

        ext_buck_vufs12@56 {
            compatible = "mediatek,ext_buck_vufs12";
            reg = <0x56>;
            regulator-name = "ext_buck_vufs12";
            regulator-min-microvolt = <300000>;
            regulator-max-microvolt = <1300000>;
            regulator-always-on;
            status = "disabled";
        };
};
&i2c9 {
        ext_buck_vmddr@51 {
            compatible = "mediatek,ext_buck_vmddr";
            reg = <0x51>;
            regulator-name = "ext_buck_vmddr";
            regulator-min-microvolt = <300000>;
            regulator-max-microvolt = <1300000>;
            status = "okay";
        };

        ext_buck_vufs12@56 {
            compatible = "mediatek,ext_buck_vufs12";
            reg = <0x56>;
            regulator-name = "ext_buck_vufs12";
            regulator-min-microvolt = <300000>;
            regulator-max-microvolt = <1300000>;
            regulator-always-on;
            status = "okay";
        };
};

